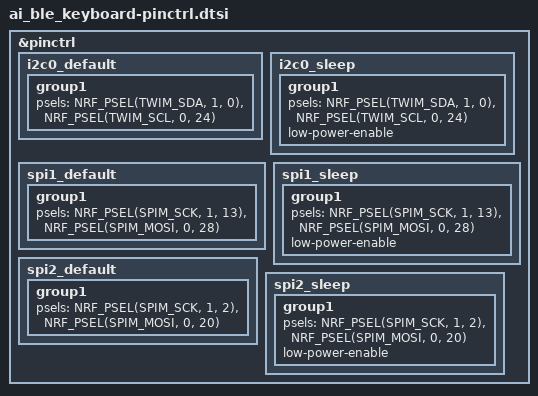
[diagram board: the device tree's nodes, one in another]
/*
 * SPDX-License-Identifier: Apache-2.0
 */

&pinctrl {
	i2c0_default: i2c0_default {
		group1 {
			psels = <NRF_PSEL(TWIM_SDA, 1, 0)>,
				<NRF_PSEL(TWIM_SCL, 0, 24)>;
		};
	};

	i2c0_sleep: i2c0_sleep {
		group1 {
			psels = <NRF_PSEL(TWIM_SDA, 1, 0)>,
				<NRF_PSEL(TWIM_SCL, 0, 24)>;
			low-power-enable;
		};
	};

	spi1_default: spi1_default {
		group1 {
			psels = <NRF_PSEL(SPIM_SCK, 1, 13)>,
				<NRF_PSEL(SPIM_MOSI, 0, 28)>;
		};
	};

	spi1_sleep: spi1_sleep {
		group1 {
			psels = <NRF_PSEL(SPIM_SCK, 1, 13)>,
				<NRF_PSEL(SPIM_MOSI, 0, 28)>;
			low-power-enable;
		};
	};

	spi2_default: spi2_default {
		group1 {
			psels = <NRF_PSEL(SPIM_SCK, 1, 2)>,
				<NRF_PSEL(SPIM_MOSI, 0, 20)>;
		};
	};

	spi2_sleep: spi2_sleep {
		group1 {
			psels = <NRF_PSEL(SPIM_SCK, 1, 2)>,
				<NRF_PSEL(SPIM_MOSI, 0, 20)>;
			low-power-enable;
		};
	};
};
